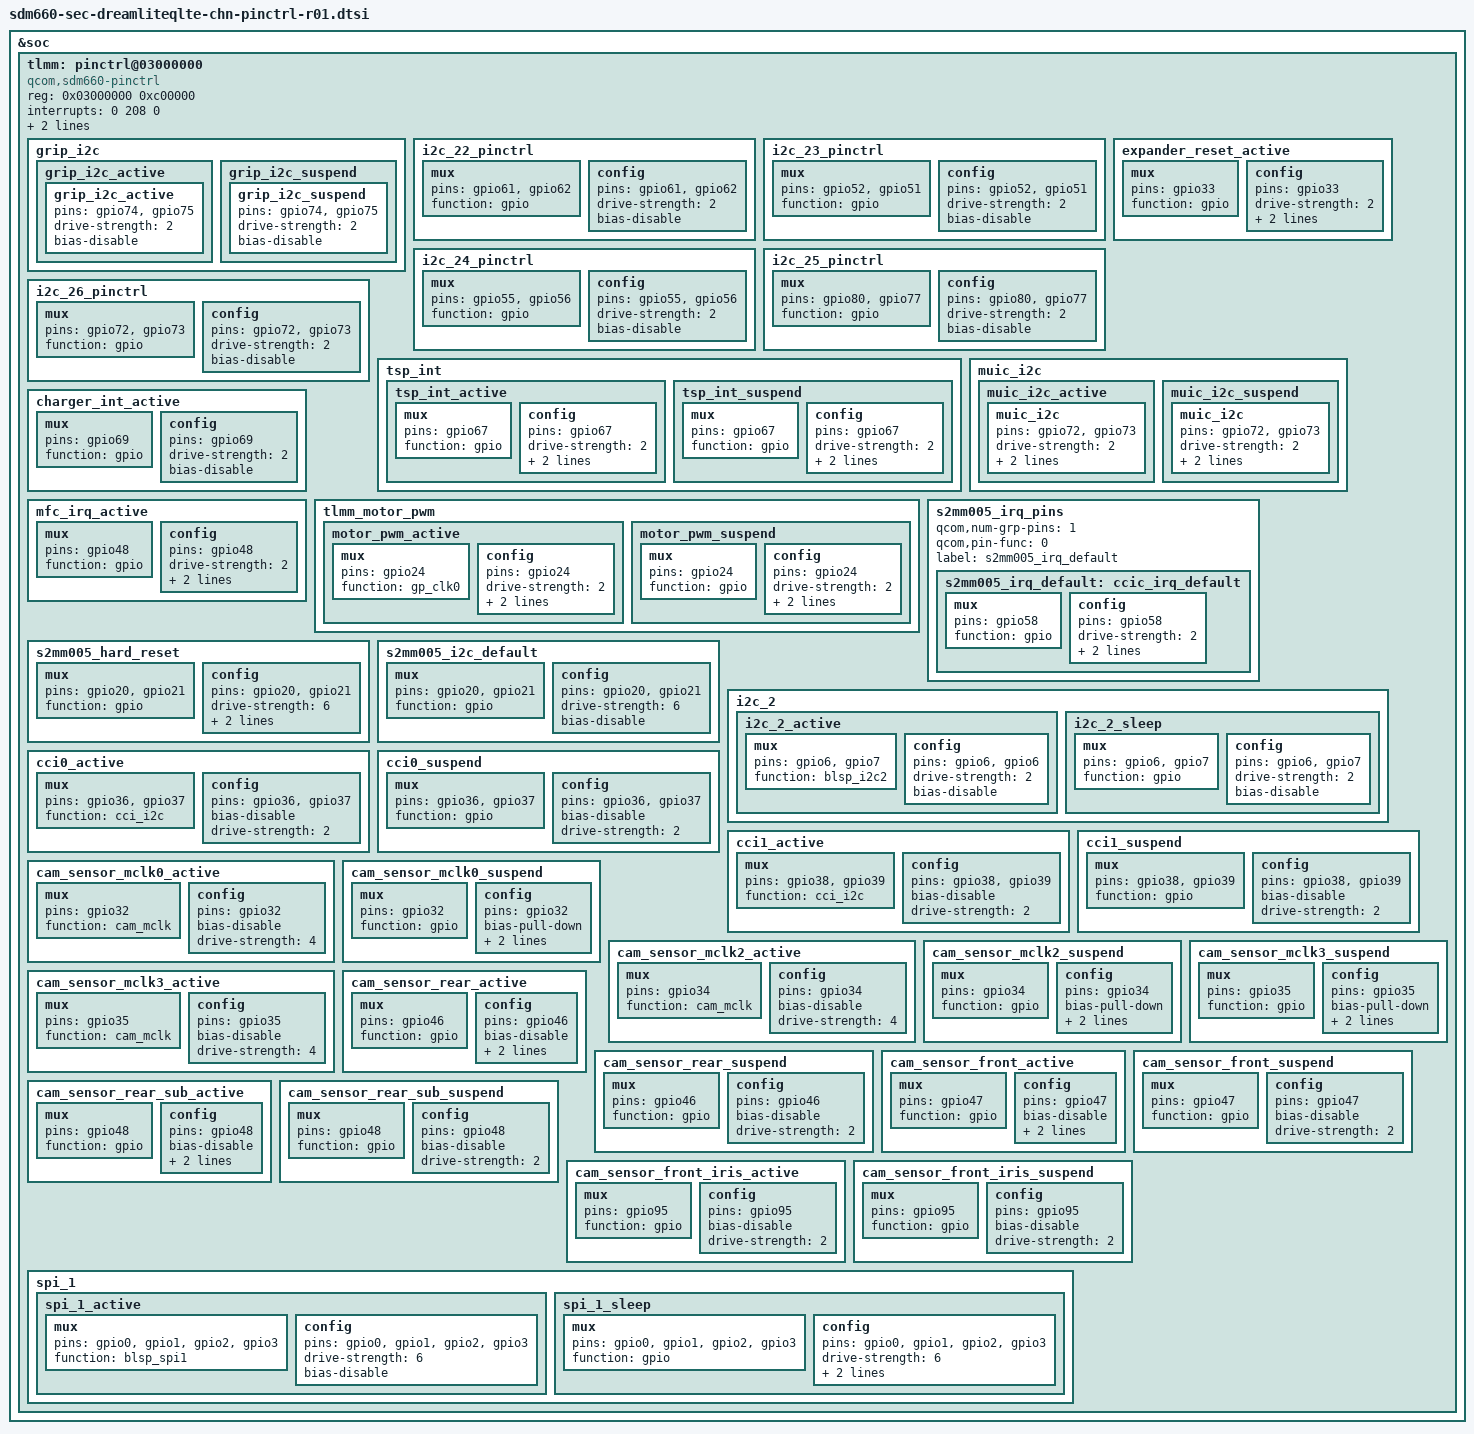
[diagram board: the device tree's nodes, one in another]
/*
 * Copyright (c) 2017, The Linux Foundation. All rights reserved.
 *
 * This program is free software; you can redistribute it and/or modify
 * it under the terms of the GNU General Public License version 2 and
 * only version 2 as published by the Free Software Foundation.
 *
 * This program is distributed in the hope that it will be useful,
 * but WITHOUT ANY WARRANTY; without even the implied warranty of
 * MERCHANTABILITY or FITNESS FOR A PARTICULAR PURPOSE.  See the
 * GNU General Public License for more details.
 */

#include "sdm660-sec-dreamliteqlte-audio-pinctrl.dtsi"

&soc {
	tlmm: pinctrl@03000000 {
		compatible = "qcom,sdm660-pinctrl";
		reg = <0x03000000 0xc00000>;
		interrupts = <0 208 0>;
		gpio-controller;
		#gpio-cells = <2>;
		interrupt-controller;
		#interrupt-cells = <2>;

		/delete-node/tlmm_gpio_key;
		/delete-node/spi_1;

		grip_i2c {
			grip_i2c_active: grip_i2c_active {
				grip_i2c_active {
					pins = "gpio74", "gpio75";
					drive-strength = <2>;
					bias-disable;
				};
			};
			grip_i2c_suspend: grip_i2c_suspend {
				grip_i2c_suspend {
					pins = "gpio74", "gpio75";
					drive-strength = <2>;
					bias-disable;
				};
			};
		};

		i2c_22_pinctrl: i2c_22_pinctrl {
			mux {
				pins = "gpio61",	/* OCTA_PMIC_SDA_1P8 */
				       "gpio62";	/* OCTA_PMIC_SDA_1P8 */
				function = "gpio";
			};
			config {
				pins = "gpio61",	/* OCTA_PMIC_SDA_1P8 */
				       "gpio62";	/* OCTA_PMIC_SDA_1P8 */
				drive-strength = <2>;
				bias-disable;
			};
		};

		i2c_23_pinctrl: i2c_23_pinctrl {
			mux {
				pins = "gpio52",	/* EXPANDER_I2C_SDA_1P8 */
				       "gpio51";	/* EXPANDER_I2C_SCL_1P8 */
				function = "gpio";
			};
			config {
				pins = "gpio52",	/* EXPANDER_I2C_SDA_1P8 */
				       "gpio51";	/* EXPANDER_I2C_SCL_1P8 */
				drive-strength = <2>;
				bias-disable;
			};
		};

		expander_reset_active: expander_reset_active {
			mux {
				pins = "gpio33";
				function = "gpio";
			};
			config {
				pins = "gpio33";
				drive-strength = <2>;   /* 16 mA */
				bias-disable;
				output-high;
			};
		};

		i2c_24_pinctrl: i2c_24_pinctrl {
			mux {
				pins = "gpio55",	/* FG_SDA_1P8 */
				       "gpio56";	/* FG_SCL_1P8 */
				function = "gpio";
			};
			config {
				pins = "gpio55",	/* FG_SDA_1P8 */
				       "gpio56";	/* FG_SCL_1P8 */
				drive-strength = <2>;
				bias-disable;
			};
		};

		i2c_25_pinctrl: i2c_25_pinctrl {
			mux {
				pins = "gpio80",	/* MFC_SDA_1P8 */
				       "gpio77";	/* MFC_SCL_1P8 */
				function = "gpio";
			};
			config {
				pins = "gpio80",	/* MFC_SDA_1P8 */
				       "gpio77";	/* MFC_SCL_1P8 */
				drive-strength = <2>;
				bias-disable;
			};
		};

		i2c_26_pinctrl: i2c_26_pinctrl {
			mux {
				pins = "gpio72",	/* IF_PMIC_SDA_1P8 */
				       "gpio73";	/* IF_PMIC_SCL_1P8 */
				function = "gpio";
			};
			config {
				pins = "gpio72",	/* IF_PMIC_SDA_1P8 */
				       "gpio73";	/* IF_PMIC_SCL_1P8 */
				drive-strength = <2>;
				bias-disable;
			};
		};

		tsp_int {
			tsp_int_active: tsp_int_active {
				mux {
					pins = "gpio67";
					function = "gpio";
				};

				config {
					pins = "gpio67";
					drive-strength = <2>;
					bias-disable;
					input-enable;
				};
			};

			tsp_int_suspend: tsp_int_suspend {
				mux {
					pins = "gpio67";
					function = "gpio";
				};

				config {
					pins = "gpio67";
					drive-strength = <2>;
					bias-disable;
					input-enable;
				};
			};
		};

		muic_i2c {
			muic_i2c_active: muic_i2c_active {
				muic_i2c {
					pins = "gpio72", "gpio73";
					drive-strength = <2>;
					function = "NA";
					bias-disable;
				};
			};
			muic_i2c_suspend: muic_i2c_suspend {
				muic_i2c {
					pins = "gpio72", "gpio73";
					drive-strength = <2>;
					function = "NA";
					bias-disable;
				};
			};
		};

		charger_int_active: charger_int_active {
			mux {
				pins = "gpio69";
				function = "gpio";
			};
			config {
				pins = "gpio69";
				drive-strength = <2>;
				bias-disable;         /* No PULL */
			};
		};

		mfc_irq_active: mfc_irq_active {
			mux {
				pins = "gpio48";
				function = "gpio";
			};
			config {
				pins = "gpio48";
				drive-strength = <2>;
				bias-disable;         /* No PULL */
				input-enable;
			};
		};

		/* add pinctrl for motor  */
		tlmm_motor_pwm {
			motor_pwm_active: motor_pwm_active {
				mux {
					pins = "gpio24";
					function = "gp_clk0";
				};
				config {
					pins = "gpio24";
					drive-strength = <2>;   /* 16 mA */
					bias-disable;
					output-high;
				};
			};
			motor_pwm_suspend: motor_pwm_suspend {
				mux {
					pins = "gpio24";
					function = "gpio";
				};
				config {
					pins = "gpio24";
					drive-strength = <2>;   /* 16 mA */
					bias-disable;
					output-low;
				};
			};
		};


		s2mm005_irq_pins {
			//qcom,pins = <&gp 58>;
			qcom,num-grp-pins = <1>;
			qcom,pin-func = <0>;
			label = "s2mm005_irq_default";
			s2mm005_irq_default: ccic_irq_default {
				mux {
					pins = "gpio58";
					function = "gpio";
				};
				config {
					pins = "gpio58";
					drive-strength = <2>;
					bias-disable;         /* No PULL */
					input-enable;
				};
			};
		};
		s2mm005_hard_reset: s2mm005_hard_reset {
				mux {
					pins = "gpio20", "gpio21";
					function = "gpio";
				};
				config {
					pins = "gpio20", "gpio21";
					drive-strength = <6>;
					bias-pull-down;
					output-low;
				};
		};

		s2mm005_i2c_default: s2mm005_i2c_default {
				mux {
					pins = "gpio20", "gpio21";
					function = "gpio";
				};
				config {
					pins = "gpio20", "gpio21";
					drive-strength = <6>;
					bias-disable;
				};
		};

		i2c_2 {
			i2c_2_active: i2c_2_active {
				mux {
					pins = "gpio6", "gpio7";
					function = "blsp_i2c2";
				};

				config {
					pins = "gpio6", "gpio6";
					drive-strength = <2>;
					bias-disable;
				};
			};

			i2c_2_sleep: i2c_2_sleep {
				mux {
					pins = "gpio6", "gpio7";
					function = "gpio";
				};

				config {
					pins = "gpio6", "gpio7";
					drive-strength = <2>;
					/delete-property/ bias-pull-up;
					bias-disable; /* No PULL */
				};
			};
		};

		cci0_active: cci0_active {
			mux {
				/* CLK, DATA */
				pins = "gpio36","gpio37"; // Only 2
				function = "cci_i2c";
			};

			config {
				pins = "gpio36","gpio37";
				bias-disable; /* No PULL */
				drive-strength = <2>; /* 2 MA */
			};
		};

		cci0_suspend: cci0_suspend {
			mux {
				/* CLK, DATA */
				pins = "gpio36","gpio37";
				function = "gpio";
			};

			config {
				pins = "gpio36","gpio37";
				/delete-property/ bias-pull-down;
				bias-disable; /* No PULL */
				drive-strength = <2>; /* 2 MA */
			};
		};

		cci1_active: cci1_active {
			mux {
				/* CLK, DATA */
				pins = "gpio38","gpio39";
				function = "cci_i2c";
			};

			config {
				pins = "gpio38","gpio39";
				bias-disable; /* No PULL */
				drive-strength = <2>; /* 2 MA */
			};
		};

		cci1_suspend: cci1_suspend {
			mux {
				/* CLK, DATA */
				pins = "gpio38","gpio39";
				function = "gpio";
			};


			config {
				pins = "gpio38","gpio39";
				/delete-property/ bias-pull-down;
				bias-disable; /* No PULL */
				drive-strength = <2>; /* 2 MA */
			};
		};

		cam_sensor_mclk0_active: cam_sensor_mclk0_active {
			/* MCLK0 */
			mux {
				/* CLK, DATA */
				pins = "gpio32";
				function = "cam_mclk";
			};

			config {
				pins = "gpio32";
				bias-disable; /* No PULL */
				drive-strength = <4>; /* 4 MA */
			};
		};

		cam_sensor_mclk0_suspend: cam_sensor_mclk0_suspend {
			/* MCLK0 */
			mux {
				/* CLK, DATA */
				pins = "gpio32";
				function = "gpio";
			};

			config {
				pins = "gpio32";
				bias-pull-down; /* PULL DOWN */
				drive-strength = <4>; /* 4 MA */
				output-low;
			};
		};

		cam_sensor_mclk2_active: cam_sensor_mclk2_active {
			/* MCLK2 */
			mux {
				/* CLK, DATA */
				pins = "gpio34";
				function = "cam_mclk";
			};

			config {
				pins = "gpio34";
				bias-disable; /* No PULL */
				drive-strength = <4>; /* 4 MA */
			};
		};

		cam_sensor_mclk2_suspend: cam_sensor_mclk2_suspend {
			/* MCLK2 */
			mux {
				/* CLK, DATA */
				pins = "gpio34";
				function = "gpio";
			};

			config {
				pins = "gpio34";
				bias-pull-down; /* PULL DOWN */
				drive-strength = <4>; /* 4 MA */
				output-low;
			};
		};

		cam_sensor_mclk3_active: cam_sensor_mclk3_active {
			/* MCLK3 */
			mux {
				/* CLK, DATA */
				pins = "gpio35";
				function = "cam_mclk";
			};

			config {
				pins = "gpio35";
				bias-disable; /* No PULL */
				drive-strength = <4>; /* 4 MA */
			};
		};

		cam_sensor_mclk3_suspend: cam_sensor_mclk3_suspend {
			/* MCLK3 */
			mux {
				/* CLK, DATA */
				pins = "gpio35";
				function = "gpio";
			};

			config {
				pins = "gpio35";
				bias-pull-down; /* PULL DOWN */
				drive-strength = <4>; /* 4 MA */
				output-low;
			};
		};

		cam_sensor_rear_active: cam_sensor_rear_active {
			/* RESET */
			mux {
				pins = "gpio46";
				function = "gpio";
			};

			config {
				pins = "gpio46";
				bias-disable; /* No PULL */
				drive-strength = <2>; /* 2 MA */
				output-low;
			};
		};

		cam_sensor_rear_suspend: cam_sensor_rear_suspend {
			/* RESET */
			mux {
				pins = "gpio46";
				function = "gpio";
			};

			config {
				pins = "gpio46";
				bias-disable; /* No PULL */
				drive-strength = <2>; /* 2 MA */
			};
		};

		cam_sensor_front_active: cam_sensor_front_active {
			/* RESET*/
			mux {
				pins = "gpio47";
				function = "gpio";
			};

			config {
				pins = "gpio47";
				bias-disable; /* No PULL */
				drive-strength = <2>; /* 2 MA */
				output-low;
			};
		};

		cam_sensor_front_suspend: cam_sensor_front_suspend {
			/* RESET */
			mux {
				pins = "gpio47";
				function = "gpio";
			};
			config {
				pins = "gpio47";
				bias-disable; /* No PULL */
				drive-strength = <2>; /* 2 MA */
			};
		};

		cam_sensor_rear_sub_active: cam_sensor_rear_sub_active {
			/* RESET */
			mux {
				pins = "gpio48";
				function = "gpio";
			};

			config {
				pins = "gpio48";
				bias-disable; /* No PULL */
				drive-strength = <2>; /* 2 MA */
				output-low;
			};
		};

		cam_sensor_rear_sub_suspend: cam_sensor_rear_sub_suspend {
			/* RESET */
			mux {
				pins = "gpio48";
				function = "gpio";
			};

			config {
				pins = "gpio48";
				bias-disable; /* No PULL */
				drive-strength = <2>; /* 2 MA */
			};
		};

		cam_sensor_front_iris_active: cam_sensor_front_iris_active {
			/* RESET */
			mux {
				pins = "gpio95";
				function = "gpio";
			};

			config {
				pins = "gpio95";
				bias-disable; /* No PULL */
				drive-strength = <2>; /* 2 MA */
			};
		};

		cam_sensor_front_iris_suspend: cam_sensor_front_iris_suspend {
			/* RESET */
			mux {
				pins = "gpio95";
				function = "gpio";
			};

			config {
				pins = "gpio95";
				bias-disable; /* No PULL */
				drive-strength = <2>; /* 2 MA */
			};
		};

		spi_1 {
			spi_1_active: spi_1_active {
			      mux {
				      pins = "gpio0", "gpio1",
					   "gpio2", "gpio3";
				      function = "blsp_spi1";
			      };
			      config {
				      pins = "gpio0", "gpio1",
					   "gpio2", "gpio3";
				      drive-strength = <6>;
				      bias-disable;
			      };
		      };

			spi_1_sleep: spi_1_sleep {
			     mux {
				     pins = "gpio0", "gpio1",
					  "gpio2", "gpio3";
				     function = "gpio";
			     };

			     config {
				     pins = "gpio0", "gpio1",
					  "gpio2", "gpio3";
				     drive-strength = <6>;
				     bias-pulll-down;
				     output-low;
			     };
		     };
	      };
	};
};
